# STM32WB15xx register map
File version: 1.0
Registers are 32-bit, read-write, reset 0x0 unless marked. A register's access mark holds for its fields unless they carry their own. Offsets are from the block's base; [hi:lo] are bit positions; {n}, {i} and the like mark numbered series.

## RNG
Base 0x58001000
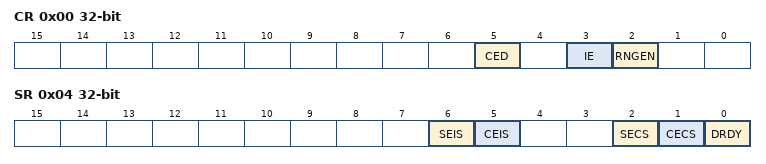
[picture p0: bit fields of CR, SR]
0x00 CR — RNG control register
  [5] CED, [3] IE, [2] RNGEN
0x04 SR — RNG status register
  [6] SEIS, [5] CEIS, [2] SECS, [1] CECS, [0] DRDY
0x08 DR — RNG data register

## HSEM — HW Semaphore HSEM
Base 0x58001400
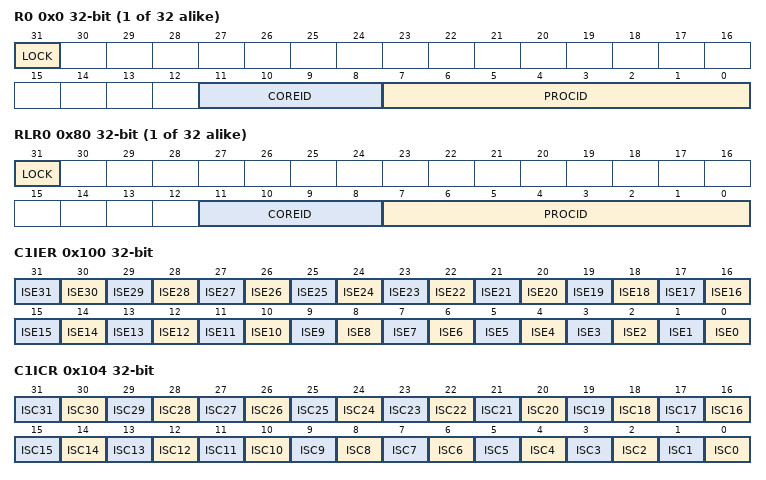
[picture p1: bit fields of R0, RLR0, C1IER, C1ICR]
{0x0+4i} R{i} (i=0..31) — HSEM 2-step write lock and read back registers
  [31] LOCK — Lock indication
  [11:8] COREID — Semaphore CoreID
    0=NONE; 4=CPU1; 8=CPU2
  [7:0] PROCID — Semaphore ProcessID
{0x80+4i} RLR{i} (i=0..31) — HSEM 1-step read lock registers
  [31] LOCK — Lock indication
  [11:8] COREID — Semaphore CoreID
  [7:0] PROCID — Semaphore ProcessID
0x100 C1IER — HSEM CPU1 interrupt enable register
  [n] ISE{n} (n=0..31) — semaphore {n} CPU1 interrupt enable bit
0x104 C1ICR — HSEM CPU1 interrupt clear register
  [n] ISC{n} (n=0..31) — semaphore {n} CPU1 interrupt clear bit
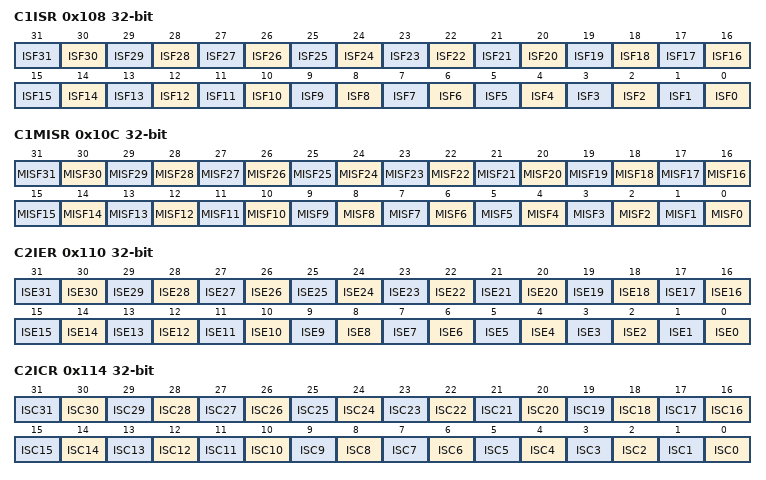
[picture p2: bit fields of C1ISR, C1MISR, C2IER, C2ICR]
0x108 C1ISR — HSEM CPU1 interrupt status register
  [n] ISF{n} (n=0..31) — semaphore {n} CPU1 interrupt status bit
0x10C C1MISR — HSEM CPU1 masked interrupt status register
  [n] MISF{n} (n=0..31) — semaphore {n} CPU1 interrupt masked status bit
0x110 C2IER — HSEM CPU2 interrupt enable register
  [n] ISE{n} (n=0..31) — semaphore {n} CPU2 interrupt enable bit
0x114 C2ICR — HSEM CPU2 interrupt clear register
  [n] ISC{n} (n=0..31) — semaphore {n} CPU2 interrupt clear bit
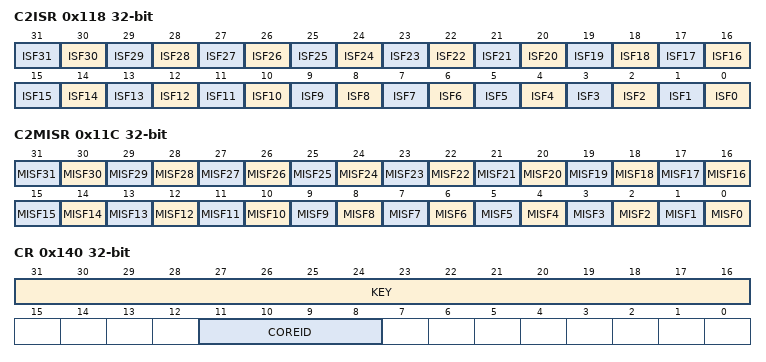
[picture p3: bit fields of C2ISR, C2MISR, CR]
0x118 C2ISR — HSEM CPU2 interrupt status register
  [n] ISF{n} (n=0..31) — semaphore {n} CPU2 interrupt status bit
0x11C C2MISR — HSEM CPU2 masked interrupt status register
  [n] MISF{n} (n=0..31) — semaphore {n} CPU2 interrupt masked status bit
0x140 CR — HSEM Semaphore clear register
  [31:16] KEY — semaphores clear key
  [11:8] COREID — CoreID of semaphores to be cleared
0x144 KEYR — HSEM Semaphore clear key register
  [31:16] KEY — semaphores clear key

## AES2 — AES hardware accelerator
Base 0x58001800
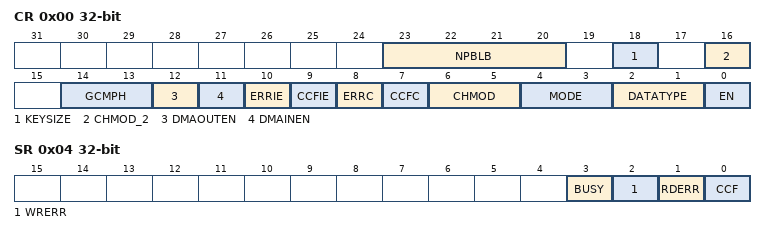
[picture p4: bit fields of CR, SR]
0x00 CR — AES control register
  [23:20] NPBLB — Number of padding bytes in last payload block
  [18] KEYSIZE — Key size selection
  [16] CHMOD_2 — AES Chaining Mode
  [14:13] GCMPH — GCM Phase
  [12] DMAOUTEN — Enable data output phase DMA management
  [11] DMAINEN — Enable data input phase DMA management
  [10] ERRIE — Error Interrupt Enable
  [9] CCFIE — Computation Complete Flag Interrupt Enable
  [8] ERRC — Error Clear
  [7] CCFC — Computation Complete Flag Clear
  [6:5] CHMOD — AES Chaining Mode
  [4:3] MODE — AES Mode Of Operation
  [2:1] DATATYPE — Data type selection
  [0] EN — AES Enable
0x04 SR — AES status register
  [3] BUSY — Busy Flag
  [2] WRERR — Write Error Flag
  [1] RDERR — Read Error Flag
  [0] CCF — Computation Complete Flag
0x08 DINR — AES data input register
  [31:0] DINR — AES Data Input Register
0x0C DOUTR — AES data output register
  [31:0] DOUTR — AES Data Output Register
{0x10+4i} KEYR{i} (i=0..3) — AES key register {i}
  [31:0] KEYR{i} — AES Key Register {i}
{0x20+4i} IVR{i} (i=0..3) — AES initialization vector register {i}
  [31:0] IVR{i} — AES Initialization Vector Register {i}
{0x20+4i} KEYR{i} (i=4..7) — AES key register {i}
  [31:0] KEYR{i} — AES Key Register {i}
{0x40+4i} SUSP{i}R (i=0..7) — AES Suspend register {i}
  [31:0] SUSP{i}R — AES Suspend registers {i}

## PKA — Public Key Accelerator (PKA)
Base 0x58002000
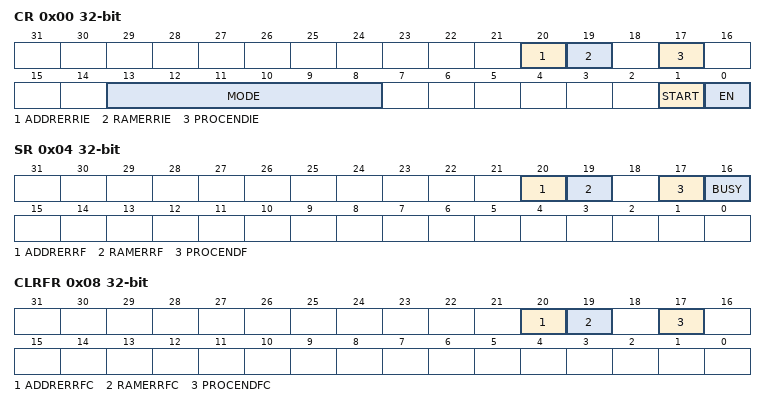
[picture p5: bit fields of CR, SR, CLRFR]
0x00 CR — PKA control register
  [20] ADDRERRIE — RAM error interrupt enable
  [19] RAMERRIE — RAM error interrupt enable
  [17] PROCENDIE — End of operation interrupt enable
  [13:8] MODE — MODE[5:0] PKA operation code
  [1] START — Start operation
  [0] EN — PKA enable
0x04 SR — PKA status register
  [20] ADDRERRF — Address error flag
  [19] RAMERRF — PKA RAM error flag
  [17] PROCENDF — PKA end of operation flag
  [16] BUSY — PKA operation is in progress
0x08 CLRFR — PKA clear flag register
  [20] ADDRERRFC — Clear address error flag
  [19] RAMERRFC — Clear PKA RAM error flag
  [17] PROCENDFC — Clear PKA end of operation flag
{0x400+4i} RAM[{i}] (i=0..893)

## DBGMCU — Debug MCU
Base 0xE0042000
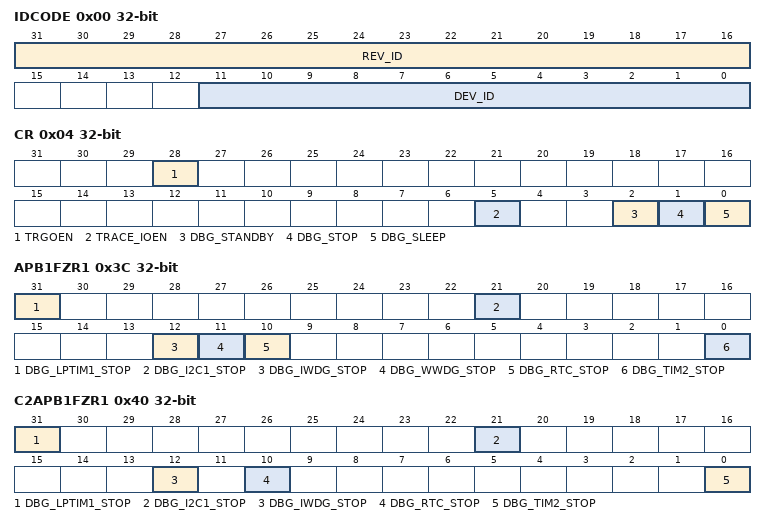
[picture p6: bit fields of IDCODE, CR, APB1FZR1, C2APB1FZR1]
0x00 IDCODE — MCU device ID code
  [31:16] REV_ID, [11:0] DEV_ID
0x04 CR — Debug MCU configuration register
  [28] TRGOEN, [5] TRACE_IOEN, [2] DBG_STANDBY, [1] DBG_STOP, [0] DBG_SLEEP
0x3C APB1FZR1 — Debug MCU CPU1 APB1 freeze register
  [31] DBG_LPTIM1_STOP, [21] DBG_I2C1_STOP, [12] DBG_IWDG_STOP, [11] DBG_WWDG_STOP, [10] DBG_RTC_STOP, [0] DBG_TIM2_STOP
0x40 C2APB1FZR1 — Debug MCU CPU2 APB1 freeze register
  [31] DBG_LPTIM1_STOP, [21] DBG_I2C1_STOP, [12] DBG_IWDG_STOP, [10] DBG_RTC_STOP, [0] DBG_TIM2_STOP
0x44 APB1FZR2 — Debug MCU CPU1 APB1 freeze register
  [5] DBG_LPTIM2_STOP
0x48 C2APB1FZR2 — Debug MCU CPU2 APB1 freeze register
  [5] DBG_LPTIM2_STOP
0x4C APB2FZR — Debug MCU CPU1 APB2 freeze register
  [11] DBG_TIM1_STOP
0x50 C2APB2FZR — Debug MCU CPU2 APB2 freeze register
  [11] DBG_TIM1_STOP
